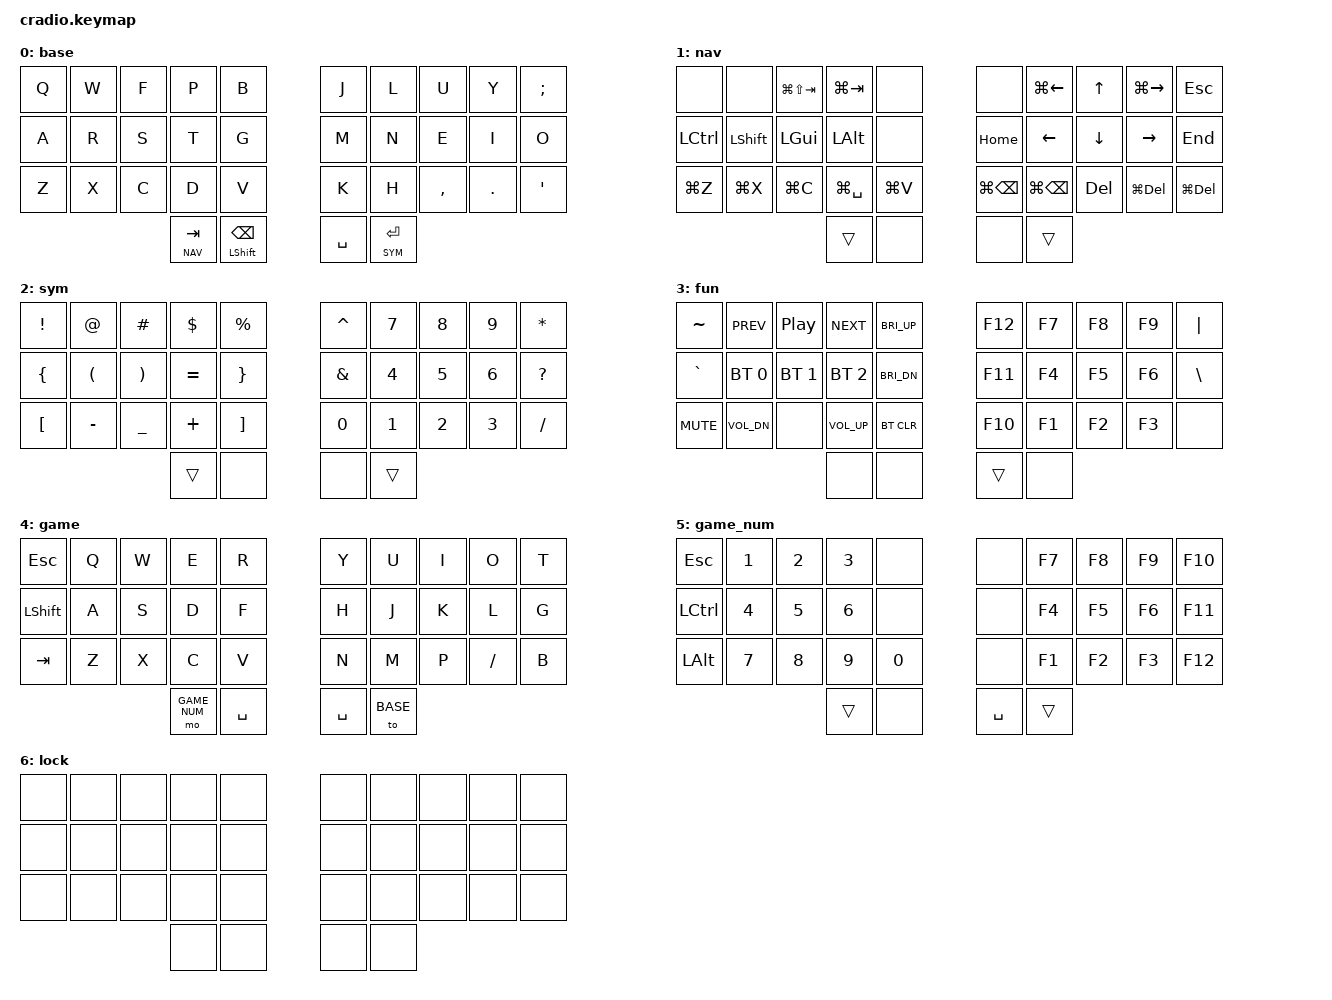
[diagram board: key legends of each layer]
// Copyright (c) 2022 The ZMK Contributors
// SPDX-License-Identifier: MIT

#include <behaviors.dtsi>               
#include <dt-bindings/zmk/keys.h>
#include <dt-bindings/zmk/bt.h>
#include <dt-bindings/zmk/outputs.h>

#define xx &none

#define ZH_LL &lt_h NAV TAB
#define ZH_LR &ht_h LSHFT BSPC
#define ZH_RL &kp SPACE
#define ZH_RR &lt_h SYM RET

#define tab_l &kp LG(LS(TAB))
#define tab_r &kp LG(TAB)

#define wrd_l &kp LG(LEFT)
#define wrd_r &kp LG(RIGHT)

#define lne_l &kp HOME
#define lne_r &kp END

#define d_wrd_l &kp LG(BSPC)
#define d_wrd_r &kp LG(DEL)

#define d_lne_l &kp LG(BSPC)
#define d_lne_r &kp LG(DEL)

// Layers
#define BASE 0
#define NAV 1
#define SYM 2
#define FUN 3
#define GAME 4
#define GAME_NUM 5
#define LOCK 6

/ {
    combos {
        compatible = "zmk,combos";
        combo_game {
            timeout-ms = <50>;
            key-positions = <32 33>;
            bindings = <&to GAME>;
            layers = <BASE>;
        };
        combo_lock {
            timeout-ms = <50>;
            key-positions = <9 19 29>;
            bindings = <&to LOCK>;
            layers = <BASE>;
        };
        combo_usb {
            timeout-ms = <50>;
            key-positions = <0 10 20>;
            bindings = <&out OUT_USB>;
            layers = <BASE>;
        };
        combo_ble {
            timeout-ms = <50>;
            key-positions = <1 11 21>;
            bindings = <&out OUT_BLE>;
            layers = <BASE>;
        };
        combo_home {
            timeout-ms = <50>;
            key-positions = <1 2>;
            bindings = <&kp HOME>;
            layers = <BASE>;
        };
        combo_lctrl {
            timeout-ms = <50>;
            key-positions = <20 21>;
            bindings = <&sk LCTRL>;
            layers = <BASE>;
        };
        combo_lgui {
            timeout-ms = <50>;
            key-positions = <21 22>;
            bindings = <&sk LGUI>;
            layers = <BASE>;
        };
        combo_lalt {
            timeout-ms = <50>;
            key-positions = <22 23>;
            bindings = <&sk LALT>;
            layers = <BASE>;
	    };
        combo_lhyper {
            timeout-ms = <50>;
            key-positions = <23 24>;
            bindings = <&sk LC(LA(LS(LGUI)))>;
            layers = <BASE>;
	    };
        combo_rhyper {
            timeout-ms = <50>;
            key-positions = <25 26>;
            bindings = <&sk LC(LA(LS(LGUI)))>;
            layers = <BASE>;
	    };
        combo_ralt {
            timeout-ms = <50>;
            key-positions = <26 27>;
            bindings = <&sk LALT>;
            layers = <BASE>;
	    };
        combo_rgui {
            timeout-ms = <50>;
            key-positions = <27 28>;
            bindings = <&sk LGUI>;
            layers = <BASE>;
        };
        combo_rctrl {
            timeout-ms = <50>;
            key-positions = <28 29>;
            bindings = <&sk LCTRL>;
            layers = <BASE>;
        };
    };

    behaviors {
        ht_t: hold_tap_tap_preferred {
            compatible = "zmk,behavior-hold-tap";
            label = "hold_tap_tap_preferred";
            #binding-cells = <2>;
            tapping-term-ms = <300>;
            quick_tap_ms = <0>;
            flavor = "tap-preferred";
            bindings = <&kp>, <&kp>;
        };
        ht_h: hold_tap_hold_preferred {
            compatible = "zmk,behavior-hold-tap";
            label = "hold_tap_hold_preferred";
            #binding-cells = <2>;
            tapping-term-ms = <300>;
	    quick_tap_ms = <0>;
            flavor = "hold-preferred";
            bindings = <&kp>, <&kp>;
        };
        lt_t: layer_tap_tap_preferred {
            compatible = "zmk,behavior-hold-tap";
            label = "layer_tap_tap_preferred";
            #binding-cells = <2>;
            tapping-term-ms = <300>;
            quick_tap_ms = <0>;
            flavor = "tap-preferred";
            bindings = <&mo>, <&kp>;
        };
        lt_h: layer_tap_hold_preferred {
            compatible = "zmk,behavior-hold-tap";
            label = "layer_tap_hold_preferred";
            #binding-cells = <2>;
            tapping-term-ms = <300>;
            quick_tap_ms = <0>;
            flavor = "hold-preferred";
            bindings = <&mo>, <&kp>;
        };
    };

    conditional_layers {
        compatible = "zmk,conditional-layers";
        tri_layer {
            if-layers = <NAV SYM>;
            then-layer = <FUN>;
        };
    };

    keymap {
        compatible = "zmk,keymap";

        base {
            bindings = <
        //╭──────────┬──────────┬──────────┬──────────┬──────────╮   ╭──────────┬──────────┬──────────┬──────────┬──────────╮
        //│  Q       │  W       │  F       │  P       │  B       │   │  J       │  L       │  U       │  Y       │ ; :      │
            &kp Q      &kp W      &kp F      &kp P      &kp B          &kp J      &kp L      &kp U      &kp Y      &kp SEMI
        //├──────────┼──────────┼──────────┼──────────┼──────────┤   ├──────────┼──────────┼──────────┼──────────┼──────────┤
        //│  A       │  R       │  S       │  T       │  G       │   │  M       │  N       │  E       │  I       │  O       │
            &kp A      &kp R      &kp S      &kp T       &kp G          &kp M     &kp N      &kp E      &kp I      &kp O
        //├──────────┼──────────┼──────────┼──────────┼──────────┤   ├──────────┼──────────┼──────────┼──────────┼──────────┤
        //│  Z       │  X       │  C       │  D       │  V       │   │  K       │  H       │ , <      │ . >      │ ' "      │
            &kp Z      &kp X      &kp C      &kp D      &kp V          &kp K      &kp H      &kp COMMA  &kp DOT    &kp SQT
        //╰──────────┴──────────┴──────────┼──────────┼──────────┤   ├──────────┼──────────┼──────────┴──────────┴──────────╯
                                ZH_LL            ZH_LR                 ZH_RL            ZH_RR
        //                    ╰────────────────┴─────────────────╯   ╰────────────────┴─────────────────╯
             >;
        };

        nav {
            bindings = <
        //╭──────────┬──────────┬──────────┬──────────┬──────────╮   ╭──────────┬──────────┬──────────┬──────────┬──────────╮
        //│          │          │  TAB_L   │  TAB_L   │          │   │          │  WRD_L   │  UP      │  WRD_R   │  Esc     │
            xx         xx         tab_l      tab_r      xx             xx         wrd_l      &kp UP     wrd_r      &kp ESC
        //├──────────┼──────────┼──────────┼──────────┼──────────┤   ├──────────┼──────────┼──────────┼──────────┼──────────┤
        //│  LCTRL   │  LSHFT   │  LCMD    │  LALT    │          │   │  LNE_L   │  LEFT    │  DOWN    │  RIGHT   │  LNE_R   │
            &kp LCTRL  &kp LSHFT  &kp LGUI   &kp LALT   xx             lne_l      &kp LEFT   &kp DOWN   &kp RIGHT  lne_r
        //├──────────┼──────────┼──────────┼──────────┼──────────┤   ├──────────┼──────────┼──────────┼──────────┼──────────┤
        //│  CMD Z   │  CMD X   │  CMD C   │  CMD SPC │  CMD V   │   │  D_LNE_L │  D_WRD_L │  DEL     │  D_WRD_R │  D_LNE_R │
            &kp LG(Z)  &kp LG(X)  &kp LG(C)  &kp LG(SPACE)&kp LG(V)    d_lne_l    d_wrd_l    &kp DEL    d_wrd_r    d_lne_r
        //╰──────────┴──────────┴──────────┼──────────┼──────────┤   ├──────────┼──────────┼──────────┴──────────┴──────────╯
                                &trans           xx                    xx               &trans
        //                    ╰────────────────┴─────────────────╯   ╰────────────────┴─────────────────╯
             >;
        };

        sym {
            bindings = <
        //╭──────────┬──────────┬──────────┬──────────┬──────────╮   ╭──────────┬──────────┬──────────┬──────────┬──────────╮
        //│  !       │   @      │  #       │  $       │  %       │   │  ^       │  7       │  8       │  9       │  *       │
            &kp EXCL   &kp AT_SIGN &kp HASH  &kp DOLLAR &kp PERCENT    &kp CARET  &kp N7     &kp N8     &kp N9     &kp STAR
        //├──────────┼──────────┼──────────┼──────────┼──────────┤   ├──────────┼──────────┼──────────┼──────────┼──────────┤
        //│  {       │  (       │  )       │  =       │  }       │   │  &       │  4       │  5       │  6       │  ?       │
            &kp LBRC   &kp LPAR   &kp RPAR   &kp EQUAL  &kp RBRC       &kp AMPS   &kp N4     &kp N5     &kp N6     &kp QMARK
        //├──────────┼──────────┼──────────┼──────────┼──────────┤   ├──────────┼──────────┼──────────┼──────────┼──────────┤
        //│  [       │  -       │  _       │  +       │  ]       │   │  0       │  1       │  2       │  3       │  /       │
            &kp LBKT   &kp MINUS  &kp UNDER  &kp PLUS   &kp RBKT       &kp N0     &kp N1     &kp N2     &kp N3     &kp SLASH
        //╰──────────┴──────────┴──────────┼──────────┼──────────┤   ├──────────┼──────────┼──────────┴──────────┴──────────╯
                                &trans           xx                    xx               &trans
        //                    ╰────────────────┴─────────────────╯   ╰────────────────┴─────────────────╯
             >;
        };

        fun {
            bindings = <
        //╭──────────┬──────────┬──────────┬──────────┬──────────╮   ╭──────────┬──────────┬──────────┬──────────┬──────────╮
        //│  ~       │  PREV    │  PLAY    │  NEXT    │  BRIU    │   │  F12     │  F7      │  F8      │  F9      │  |       │
            &kp TILDE  &kp C_PREV &kp C_PP   &kp C_NEXT &kp C_BRI_UP   &kp F12    &kp F7     &kp F8     &kp F9     &kp PIPE
        //├──────────┼──────────┼──────────┼──────────┼──────────┤   ├──────────┼──────────┼──────────┼──────────┼──────────┤
        //│  `       │  BT 0    │  BT 1    │  BT 2    │  BRID    │   │  F11     │  F4      │  F5      │  F6      │  \       │
            &kp GRAVE &bt BT_SEL 0 &bt BT_SEL 1 &bt BT_SEL 2 &kp C_BRI_DN &kp F11 &kp F4     &kp F5     &kp F6     &kp BSLH
        //├──────────┼──────────┼──────────┼──────────┼──────────┤   ├──────────┼──────────┼──────────┼──────────┼──────────┤
        //│  MUTE    │  VOLD    │          │  VOLU    │  BT_CLR  │   │  F10     │  F1      │  F2      │  F3      │          │
            &kp C_MUTE &kp C_VOL_DN xx       &kp C_VOL_UP &bt BT_CLR   &kp F10    &kp F1     &kp F2     &kp F3     xx
        //╰──────────┴──────────┴──────────┼──────────┼──────────┤   ├──────────┼──────────┼──────────┴──────────┴──────────╯
                                xx               xx                    &trans           xx
        //                    ╰────────────────┴─────────────────╯   ╰────────────────┴─────────────────╯
             >;
        };

        game {
            bindings = <
        //╭──────────┬──────────┬──────────┬──────────┬──────────╮   ╭──────────┬──────────┬──────────┬──────────┬──────────╮
        //│  ESC     │  Q       │  W       │  E       │  R       │   │  Y       │  U       │  I       │  O       │  T       │
            &kp ESC    &kp Q      &kp W      &kp E      &kp R          &kp Y      &kp U      &kp I      &kp O      &kp T
        //├──────────┼──────────┼──────────┼──────────┼──────────┤   ├──────────┼──────────┼──────────┼──────────┼──────────┤
        //│  LSHFT   │  A       │  S       │  D       │  F       │   │  H       │  J       │  K       │  L       │  G       │
            &kp LSHFT  &kp A      &kp S      &kp D      &kp F          &kp H      &kp J      &kp K      &kp L      &kp G
        //├──────────┼──────────┼──────────┼──────────┼──────────┤   ├──────────┼──────────┼──────────┼──────────┼──────────┤
        //│  TAB     │  Z       │  X       │  C       │  V       │   │  N       │  M       │  P       │  /       │  B       │
            &kp TAB    &kp Z      &kp X      &kp C      &kp V          &kp N      &kp M      &kp P      &kp SLASH  &kp B 
        //╰──────────┴──────────┴──────────┼──────────┼──────────┤   ├──────────┼──────────┼──────────┴──────────┴──────────╯
                                &mo GAME_NUM     &kp SPACE             &kp SPACE        &to BASE
        //                    ╰────────────────┴─────────────────╯   ╰────────────────┴─────────────────╯
             >;
        };

        game_num {
            bindings = <
        //╭──────────┬──────────┬──────────┬──────────┬──────────╮   ╭──────────┬──────────┬──────────┬──────────┬──────────╮
        //│  ESC     │  1       │  2       │  3       │          │   │          │  F7      │  F8      │  F9      │  F10     │
            &kp ESC    &kp N1     &kp N2     &kp N3     xx             xx         &kp F7     &kp F8     &kp F9     &kp F10
        //├──────────┼──────────┼──────────┼──────────┼──────────┤   ├──────────┼──────────┼──────────┼──────────┼──────────┤
        //│  LCTRL   │  4       │  5       │  6       │          │   │          │  F4      │  F5      │  F6      │  F11     │
            &kp LCTRL  &kp N4     &kp N5     &kp N6     xx             xx         &kp F4     &kp F5     &kp F6     &kp F11
        //├──────────┼──────────┼──────────┼──────────┼──────────┤   ├──────────┼──────────┼──────────┼──────────┼──────────┤
        //│  LALT    │  7       │  8       │  9       │  0       │   │          │  F1      │  F2      │  F3      │  F12     │
            &kp LALT   &kp N7     &kp N8     &kp N9     &kp N0         xx         &kp F1     &kp F2     &kp F3     &kp F12
        //╰──────────┴──────────┴──────────┼──────────┼──────────┤   ├──────────┼──────────┼──────────┴──────────┴──────────╯
                                &trans           xx                    &kp SPACE        &trans
        //                    ╰────────────────┴─────────────────╯   ╰────────────────┴─────────────────╯
             >;
        };

        lock {
            bindings = <
        //╭──────────┬──────────┬──────────┬──────────┬──────────╮   ╭──────────┬──────────┬──────────┬──────────┬──────────╮
        //│          │          │          │          │          │   │          │          │          │          │          │
            xx         xx         xx         xx         xx             xx         xx         xx         xx         xx
        //├──────────┼──────────┼──────────┼──────────┼──────────┤   ├──────────┼──────────┼──────────┼──────────┼──────────┤
        //│          │          │          │          │          │   │          │          │          │          │          │
            xx         xx         xx         xx         xx             xx         xx         xx         xx         xx
        //├──────────┼──────────┼──────────┼──────────┼──────────┤   ├──────────┼──────────┼──────────┼──────────┼──────────┤
        //│          │          │          │          │          │   │          │          │          │          │          │
            xx         xx         xx         xx         xx             xx         xx         xx         xx         xx
        //╰──────────┴──────────┴──────────┼──────────┼──────────┤   ├──────────┼──────────┼──────────┴──────────┴──────────╯
                                xx               xx                    xx               xx
        //                    ╰────────────────┴─────────────────╯   ╰────────────────┴─────────────────╯
             >;
        };
       
    };
};
